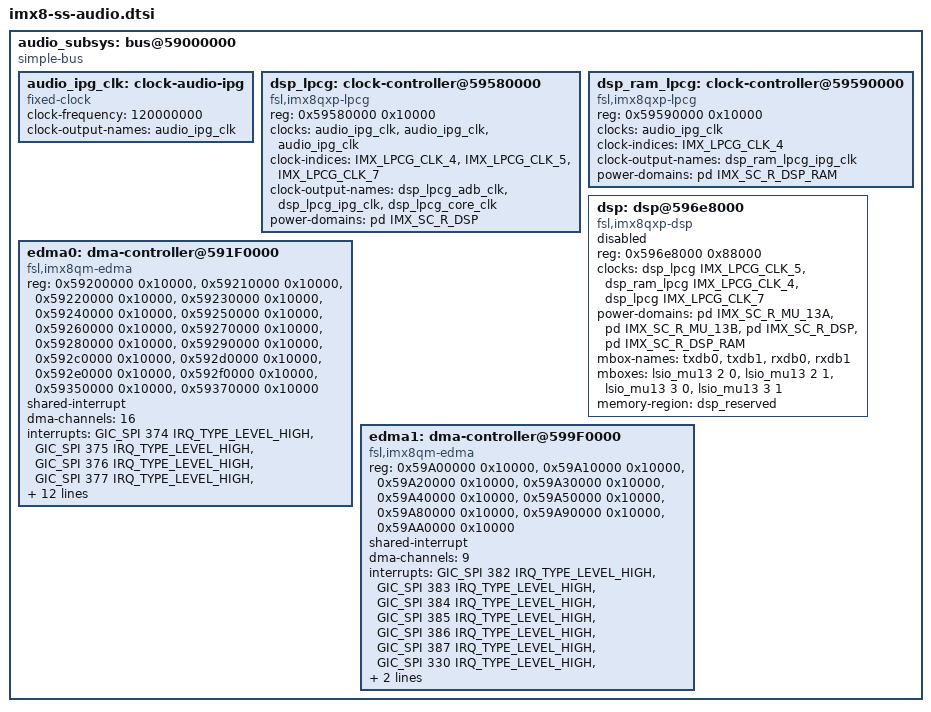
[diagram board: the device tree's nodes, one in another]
// SPDX-License-Identifier: GPL-2.0+
/*
 * Copyright 2018-2019 NXP
 *	Dong Aisheng <aisheng.dong@nxp.com>
 */

#include <dt-bindings/clock/imx8-lpcg.h>
#include <dt-bindings/firmware/imx/rsrc.h>

audio_subsys: bus@59000000 {
	compatible = "simple-bus";
	#address-cells = <1>;
	#size-cells = <1>;
	ranges = <0x59000000 0x0 0x59000000 0x1000000>;

	audio_ipg_clk: clock-audio-ipg {
		compatible = "fixed-clock";
		#clock-cells = <0>;
		clock-frequency = <120000000>;
		clock-output-names = "audio_ipg_clk";
	};

	dsp_lpcg: clock-controller@59580000 {
		compatible = "fsl,imx8qxp-lpcg";
		reg = <0x59580000 0x10000>;
		#clock-cells = <1>;
		clocks = <&audio_ipg_clk>,
			 <&audio_ipg_clk>,
			 <&audio_ipg_clk>;
		clock-indices = <IMX_LPCG_CLK_4>, <IMX_LPCG_CLK_5>,
				<IMX_LPCG_CLK_7>;
		clock-output-names = "dsp_lpcg_adb_clk",
				     "dsp_lpcg_ipg_clk",
				     "dsp_lpcg_core_clk";
		power-domains = <&pd IMX_SC_R_DSP>;
	};

	dsp_ram_lpcg: clock-controller@59590000 {
		compatible = "fsl,imx8qxp-lpcg";
		reg = <0x59590000 0x10000>;
		#clock-cells = <1>;
		clocks = <&audio_ipg_clk>;
		clock-indices = <IMX_LPCG_CLK_4>;
		clock-output-names = "dsp_ram_lpcg_ipg_clk";
		power-domains = <&pd IMX_SC_R_DSP_RAM>;
	};

	dsp: dsp@596e8000 {
		compatible = "fsl,imx8qxp-dsp";
		reg = <0x596e8000 0x88000>;
		clocks = <&dsp_lpcg IMX_LPCG_CLK_5>,
			 <&dsp_ram_lpcg IMX_LPCG_CLK_4>,
			 <&dsp_lpcg IMX_LPCG_CLK_7>;
		clock-names = "ipg", "ocram", "core";
		power-domains = <&pd IMX_SC_R_MU_13A>,
			<&pd IMX_SC_R_MU_13B>,
			<&pd IMX_SC_R_DSP>,
			<&pd IMX_SC_R_DSP_RAM>;
		mbox-names = "txdb0", "txdb1",
			"rxdb0", "rxdb1";
		mboxes = <&lsio_mu13 2 0>,
			<&lsio_mu13 2 1>,
			<&lsio_mu13 3 0>,
			<&lsio_mu13 3 1>;
		memory-region = <&dsp_reserved>;
		status = "disabled";
	};

	edma0: dma-controller@591F0000 {
		compatible = "fsl,imx8qm-edma";
		reg = <0x59200000 0x10000>, /* asrc0 */
			<0x59210000 0x10000>,
			<0x59220000 0x10000>,
			<0x59230000 0x10000>,
			<0x59240000 0x10000>,
			<0x59250000 0x10000>,
			<0x59260000 0x10000>, /* esai0 rx */
			<0x59270000 0x10000>, /* esai0 tx */
			<0x59280000 0x10000>, /* spdif0 rx */
			<0x59290000 0x10000>, /* spdif0 tx */
			<0x592c0000 0x10000>, /* sai0 rx */
			<0x592d0000 0x10000>, /* sai0 tx */
			<0x592e0000 0x10000>, /* sai1 rx */
			<0x592f0000 0x10000>, /* sai1 tx */
			<0x59350000 0x10000>,
			<0x59370000 0x10000>;
		#dma-cells = <3>;
		shared-interrupt;
		dma-channels = <16>;
		interrupts = <GIC_SPI 374 IRQ_TYPE_LEVEL_HIGH>, /* asrc 0 */
				<GIC_SPI 375 IRQ_TYPE_LEVEL_HIGH>,
				<GIC_SPI 376 IRQ_TYPE_LEVEL_HIGH>,
				<GIC_SPI 377 IRQ_TYPE_LEVEL_HIGH>,
				<GIC_SPI 378 IRQ_TYPE_LEVEL_HIGH>,
				<GIC_SPI 379 IRQ_TYPE_LEVEL_HIGH>,
				<GIC_SPI 410 IRQ_TYPE_LEVEL_HIGH>, /* esai0 */
				<GIC_SPI 410 IRQ_TYPE_LEVEL_HIGH>,
				<GIC_SPI 457 IRQ_TYPE_LEVEL_HIGH>, /* spdif0 */
				<GIC_SPI 459 IRQ_TYPE_LEVEL_HIGH>,
				<GIC_SPI 315 IRQ_TYPE_LEVEL_HIGH>, /* sai0 */
				<GIC_SPI 315 IRQ_TYPE_LEVEL_HIGH>,
				<GIC_SPI 317 IRQ_TYPE_LEVEL_HIGH>, /* sai1 */
				<GIC_SPI 317 IRQ_TYPE_LEVEL_HIGH>,
				<GIC_SPI 391 IRQ_TYPE_LEVEL_HIGH>,
				<GIC_SPI 393 IRQ_TYPE_LEVEL_HIGH>;
		interrupt-names = "edma0-chan0-rx", "edma0-chan1-rx", /* asrc0 */
				"edma0-chan2-rx", "edma0-chan3-tx",
				"edma0-chan4-tx", "edma0-chan5-tx",
				"edma0-chan6-rx", "edma0-chan7-tx", /* esai0 */
				"edma0-chan8-rx", "edma0-chan9-tx", /* spdif0 */
				"edma0-chan12-rx", "edma0-chan13-tx", /* sai0 */
				"edma0-chan14-rx", "edma0-chan15-tx", /* sai1 */
				"edma0-chan21-tx",		/* gpt5 */
				"edma0-chan23-rx";		/* gpt7 */
		status = "okay";
	};

	edma1: dma-controller@599F0000 {
		compatible = "fsl,imx8qm-edma";
		reg = <0x59A00000 0x10000>, /* asrc1 */
			<0x59A10000 0x10000>,
			<0x59A20000 0x10000>,
			<0x59A30000 0x10000>,
			<0x59A40000 0x10000>,
			<0x59A50000 0x10000>,
			<0x59A80000 0x10000>, /* sai4 rx */
			<0x59A90000 0x10000>, /* sai4 tx */
			<0x59AA0000 0x10000>; /* sai5 tx */
		#dma-cells = <3>;
		shared-interrupt;
		dma-channels = <9>;
		interrupts = <GIC_SPI 382 IRQ_TYPE_LEVEL_HIGH>, /* asrc 1 */
				<GIC_SPI 383 IRQ_TYPE_LEVEL_HIGH>,
				<GIC_SPI 384 IRQ_TYPE_LEVEL_HIGH>,
				<GIC_SPI 385 IRQ_TYPE_LEVEL_HIGH>,
				<GIC_SPI 386 IRQ_TYPE_LEVEL_HIGH>,
				<GIC_SPI 387 IRQ_TYPE_LEVEL_HIGH>,
				<GIC_SPI 330 IRQ_TYPE_LEVEL_HIGH>, /* sai4 */
				<GIC_SPI 330 IRQ_TYPE_LEVEL_HIGH>,
				<GIC_SPI 332 IRQ_TYPE_LEVEL_HIGH>; /* sai5 */
		interrupt-names = "edma1-chan0-rx", "edma1-chan1-rx", /* asrc1 */
				"edma1-chan2-rx", "edma1-chan3-tx",
				"edma1-chan4-tx", "edma1-chan5-tx",
				"edma1-chan8-rx", "edma1-chan9-tx", /* sai4 */
				"edma1-chan10-tx";                 /* sai5 */
		status = "okay";
	};
};
